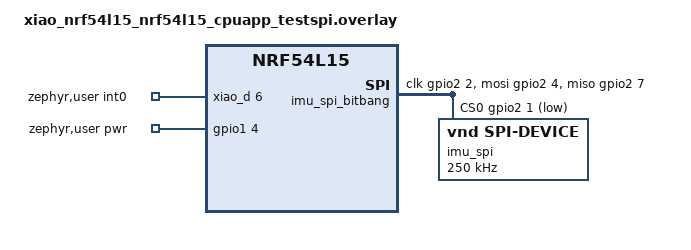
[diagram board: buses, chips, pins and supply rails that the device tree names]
/*
 * External software-SPI IMU test variant (-DFILE_SUFFIX=testspi).
 * Same XIAO connector positions as the LM20A testspi variant, with the
 * nRF54L15 GPIO mapping:
 *   D0  (P1.04) -> 3V3 (active-high sensor power)
 *   D10 (P2.02) -> SCL (SPI SCK)
 *   D9  (P2.04) -> SDA (SPI MOSI / SDI)
 *   D8  (P2.01) -> CS
 *   D7  (P2.07) -> SDO (SPI MISO)
 *   D6  (P2.08) -> INT
 *   GND         -> GND
 * These wires cannot use nRF54L15 SPIM00's dedicated signal routing.
 * Bitbang SPI preserves them for validation, not full-rate performance.
 * The base overlay already disables uart21 on D6/D7; the uart20 console
 * remains available through the SAMD11 bridge.
 */
#include "xiao_nrf54l15_nrf54l15_cpuapp.overlay"

/* Replace the inherited hardware child while keeping the scanner's label. */
/delete-node/ &imu_spi;

&spi00 {
	status = "disabled";
};

/ {
	imu_spi_bitbang: spi-bitbang {
		compatible = "zephyr,spi-bitbang";
		status = "okay";
		#address-cells = <1>;
		#size-cells = <0>;
		clk-gpios = <&gpio2 2 GPIO_ACTIVE_HIGH>;
		mosi-gpios = <&gpio2 4 GPIO_ACTIVE_HIGH>;
		miso-gpios = <&gpio2 7 GPIO_ACTIVE_HIGH>;
		cs-gpios = <&gpio2 1 GPIO_ACTIVE_LOW>;

		imu_spi: imu@0 {
			compatible = "vnd,spi-device";
			reg = <0>;
			/* 2 us per half-cycle, plus software/GPIO overhead. */
			spi-max-frequency = <250000>;
		};
	};

	zephyr,user {
		int0-gpios = <&xiao_d 6 GPIO_ACTIVE_HIGH>;
		pwr-gpios = <&gpio1 4 GPIO_ACTIVE_HIGH>;
	};
};

/* SPI-only sensor scan, matching the LM20A test variant. */
&i2c22 {
	status = "disabled";
};

&imu {
	status = "disabled";
};

&mag {
	status = "disabled";
};
